# MB9B160R register map
File version: 1.3
MB9B160R Series
CPU: 
Registers are 8-bit, read-write, reset 0x0 unless marked. A register's access mark holds for its fields unless they carry their own. Offsets are from the block's base; lines under a group give offsets from that group; [hi:lo] are bit positions; {n}, {i} and the like mark numbered series; 'fields as' and 'values as' point back to an identical list; <NAME> marks a mode.

## Memory map
0x200E0000 WORKFLASH_IF size 0xC — WorkFlash Memory
0x40000000 FLASH_IF size 0xC — Flash Memory
0x40000200 UNIQUE_ID size 0x4
0x40000300 ECC_CAPTURE size 0x4 — ECC Capture Address
0x40010000 CRG size 0x70 — Clock Unit Registers
0x40011000 HWWDT size 0x4 — Hardware Watchdog Timer
0x40012000 SWWDT size 0x4 — Software Watchdog Timer
0x40015000 DTIM size 0x1C — Dual Timer
0x40020000 MFT0 size 0x1EC — Multifunction Timer 0
0x40021000 MFT1 size 0x1EC — Multifunction Timer 0
0x40024000 MFT_PPG size 0x2 — PPG Configuration
0x40025000 BT0 size 0x2 — Base Timer 0
0x40025040 BT1 size 0x2 — Base Timer 0
0x40025080 BT2 size 0x2 — Base Timer 0
0x400250C0 BT3 size 0x2 — Base Timer 0
0x40025100 BTIOSEL03 size 0x2 — Base Timer I/O Select
0x40025200 BT4 size 0x2 — Base Timer 0
0x40025240 BT5 size 0x2 — Base Timer 0
0x40025280 BT6 size 0x2 — Base Timer 0
0x400252C0 BT7 size 0x2 — Base Timer 0
0x40025300 BTIOSEL47 size 0x2 — Base Timer I/O Select
0x40025F00 SBSSR blocks up to offset 0xFE — Software-based Simultaneous Startup Register
0x40026000 QPRC0 size 0x2 — Quadrature Position/Revolution Counter 0
0x40026040 QPRC1 size 0x2 — Quadrature Position/Revolution Counter 0
0x40026100 QPRC0_NF size 0x1 — Quadrature Position/Revolution Counter 0 Noise Filter
0x40026110 QPRC1_NF size 0x1 — Quadrature Position/Revolution Counter 0 Noise Filter
0x40027000 ADC0 size 0x2 — ADC0 Registers
0x40027100 ADC1 size 0x2 — ADC0 Registers
0x40027200 ADC2 size 0x2 — ADC0 Registers
0x4002E000 CRTRIM size 0x1 — CR Trimming Registers
0x40030000 EXTI size 0x4 — External Interrupt and NMI Control
0x40031000 INTREQ size 0x4 — Interrupts
0x40033000 DAC0 size 0x1 — D/A Converter 0
0x40033008 DAC1 size 0x1 — D/A Converter 0
0x40035000 LVD size 0x1 — Low-voltage Detection
0x40035100 DS blocks up to offset 0x5 — Low Power Consumption Mode
{0x40038000+0x100*n} MFS{n} size 0x2 (n=0..7) — Multi-function Serial Interface 0
0x40039000 CRC size 0x1 — CRC Registers
0x4003A000 WC size 0x3 — Watch Counter
0x4003B000 RTC size 0x1B1 — REAL-TIME CLOCK
0x4003C000 LCR size 0x1 — Low-speed CR Prescaler
0x4003C100 CLK_GATING size 0x28 — Peripheral Clock Gating
0x4003C800 PLL_CONTROL size 0x8 — Main PLL Control
0x4003F000 EXBUS size 0x80 — External Bus Interface
0x40060000 DMAC size 0x4 — DMAC Registers
0x40061000 DSTC size 0xB0 — DSTC registers
0x4006E000 SDIF size 0x1000 — SD Card Interface
0x4006F000 GPIO size 0x740 — 0

## Interrupts
0 CSV (CRG)
1 SWDT (SWWDT)
2 LVD
{n+11} EXINT{n} (EXTI) (n=0..7)
19 QPRC0
20 QPRC1
21 WFG0_DTIF0 (MFT0)
22 WFG1_DTIF1 (MFT1)
24 FRT0_PEAK (MFT0)
25 FRT0_ZERO (MFT0)
26 ICU0 (MFT0)
27 OCU0 (MFT0)
28 FRT1_PEAK (MFT1)
29 FRT1_ZERO (MFT1)
30 ICU1 (MFT1)
31 OCU1 (MFT1)
36 PPG00_02_04 (MFT_PPG)
37 PPG08_10_12 (MFT_PPG)
38 PPG16_18_20 (MFT_PPG)
{n+39} BT{n} (n=0..7)
47 DT1_2 (DTIM)
48 WC
49 EXTBUS_ERR (EXBUS)
50 RTC
{n+43} EXINT{n} (EXTI) (n=8..15)
59 TIM (CRG)
{2n+60} MFS{n}_RX (MFS{n}) (n=0..7)
{2n+61} MFS{n}_TX (MFS{n}) (n=0..7)
76 ADC0
77 ADC1
{n+83} DMAC{n} (DMAC) (n=0..7)
91 DSTC
92 EXINT16_17_18_19 (EXTI)
93 EXINT20_21_22_23 (EXTI)
94 EXINT24_25_26_27 (EXTI)
95 EXINT28_29_30_31 (EXTI)
111 ADC2
118 SD (SDIF)
119 FLASH (FLASH_IF)

## WORKFLASH_IF — WorkFlash Memory
Base 0x200E0000
0x00 WFASZR 32-bit reset 0x1 — WorkFlash Access Size Register
  [0] ASZ — WorkFlash Access Size
0x04 WFRWTR 32-bit reset 0x4 — WorkFlash Read Wait Register
  [2:0] RWT — Read Wait Cycle
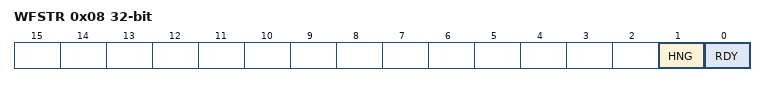
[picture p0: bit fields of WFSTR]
0x08 WFSTR 32-bit ro — WorkFlash Status Register
  [1] HNG — WorkFlash Hang
  [0] RDY — WorkFlash Rdy

## FLASH_IF — Flash Memory
Base 0x40000000
0x00 FASZR 32-bit reset 0x2 — Flash Access Size Register
  [1:0] ASZ — Access Size
0x04 FRWTR 32-bit reset 0x2 — Flash Read Wait Register
  [1:0] RWT — Read Wait Cycle
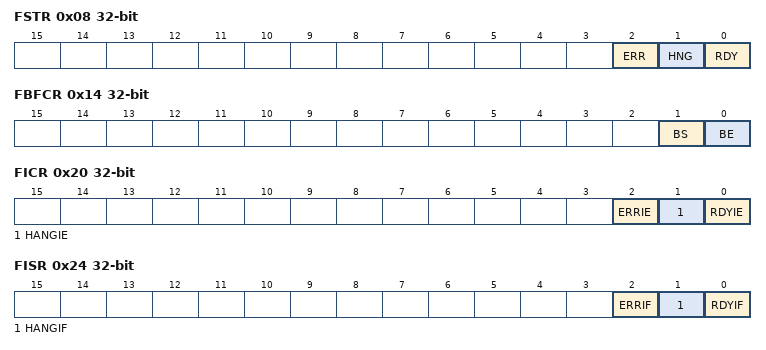
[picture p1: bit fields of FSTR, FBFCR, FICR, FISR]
0x08 FSTR 32-bit ro — Flash Status Register
  [2] ERR rw — Flash ECC Error
  [1] HNG — Flash Hang flag
  [0] RDY — Flash Rdy
0x10 FSYNDN 32-bit — Flash Sync Down Register
  [2:0] SD — Sync Down
0x14 FBFCR 32-bit — Flash Buffer Control Register
  [1] BS ro — Buffer Status
  [0] BE — Buffer Enable
0x20 FICR 32-bit — Flash Interrupt Control Register
  [2] ERRIE — Flash ECC Error Interrupt Enable
  [1] HANGIE — HANG Interrupt Enable
  [0] RDYIE — RDY Interrupt Enable
0x24 FISR 32-bit — Flash Interrupt Status Register
  [2] ERRIF ro — Flash ECC Error Interrupt Flag
  [1] HANGIF ro — HANG Interrupt Flag
  [0] RDYIF ro — RDY Interrupt Flag
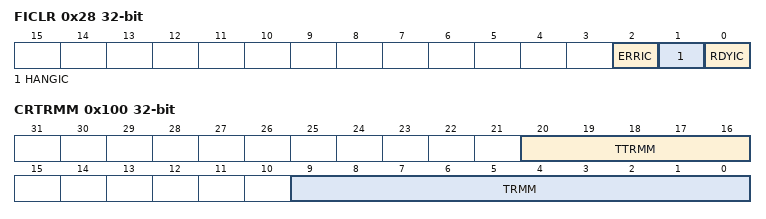
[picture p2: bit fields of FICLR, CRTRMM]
0x28 FICLR 32-bit wo — Flash Interrupt Clear Register
  [2] ERRIC rw — Flash ECC Error Interrupt Clear
  [1] HANGIC rw — HANG Interrupt Clear
  [0] RDYIC rw — RDY Interrupt Clear
0x100 CRTRMM 32-bit ro reset not defined — CR Trimming Data Mirror Register
  [20:16] TTRMM — CR Temperature Trimming Data Mirror
  [9:0] TRMM — CR Trimming Data Mirror
